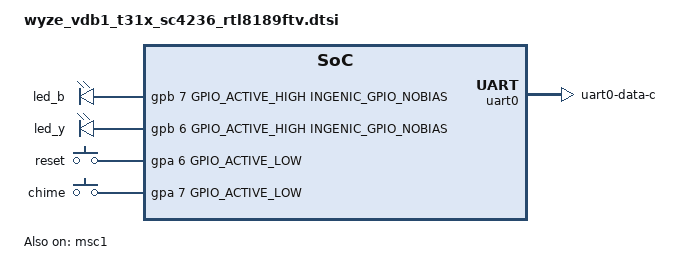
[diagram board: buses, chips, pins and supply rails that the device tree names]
// Wyze Video Doorbell v1 (T31X, SC4236, RTL8189FTV) per-board GPIO definitions.
// Injected into the kernel 4.4+ device tree; ignored on 3.10.

#include <dt-bindings/gpio/gpio.h>
#include <dt-bindings/input/input.h>
#include <dt-bindings/pinctrl/ingenic-pinctrl.h>

/ {
	gpio-leds {
		compatible = "gpio-leds";

		led_b {
			label = "led_b";
			gpios = <&gpb 7 GPIO_ACTIVE_HIGH INGENIC_GPIO_NOBIAS>;
			default-state = "off";
		};

		led_y {
			label = "led_y";
			gpios = <&gpb 6 GPIO_ACTIVE_HIGH INGENIC_GPIO_NOBIAS>;
			default-state = "off";
		};
	};
};

/ {
	gpio-keys {
		compatible = "gpio-keys";
		label = "gpio-keys";

		reset {
			label = "reset";
			linux,code = <KEY_ENTER>;
			gpios = <&gpa 6 GPIO_ACTIVE_LOW INGENIC_GPIO_PULLUP>;
		};

		chime {
			label = "chime";
			linux,code = <KEY_1>;
			gpios = <&gpa 7 GPIO_ACTIVE_LOW INGENIC_GPIO_PULLUP>;
		};
	};
};

/* SDIO WiFi is wired to MSC1 (PB8-11/PB13-14). This board has no SD card;
   leaving MSC0 enabled only produces spurious SDIO probe errors. */
&msc0 {
	status = "disabled";
};

&msc1 {
	status = "okay";
	bus-width = <4>;
	max-frequency = <24000000>;
	non-removable;
	ingenic,sdio_clk = <1>;

	pinctrl-names = "default";
	pinctrl-0 = <&msc1_pb>;
};

/* The sub-GHz chime radio is on UART0 (PC10/PC11); the console is UART1. */
&pinctrl {
	pins_uart0: uart0 {
		function = "uart0";
		groups = "uart0-data-c";
	};
};

&uart0 {
	status = "okay";

	pinctrl-names = "default";
	pinctrl-0 = <&pins_uart0>;
};
